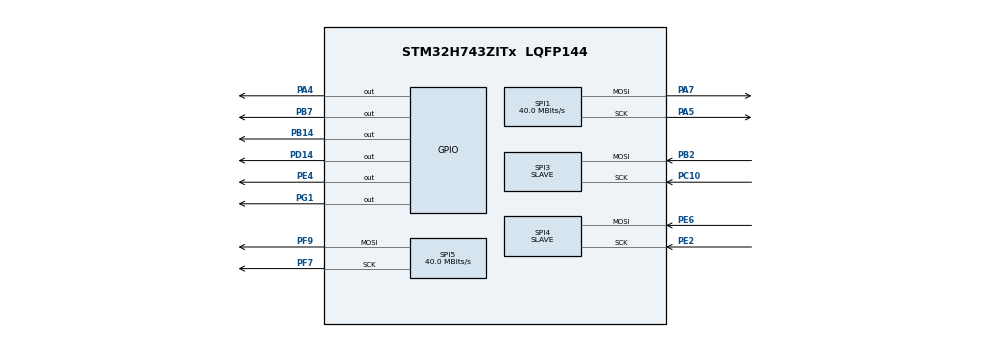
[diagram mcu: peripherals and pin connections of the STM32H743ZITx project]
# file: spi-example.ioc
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CORTEX_M7.CPU_DCache=Enabled
CORTEX_M7.CPU_ICache=Enabled
Dma.Request0=SPI3_RX
Dma.Request1=SPI1_TX
Dma.Request2=SPI5_TX
Dma.Request3=SPI4_RX
Dma.SPI1_TX.1.Direction=DMA_MEMORY_TO_PERIPH
Dma.SPI1_TX.1.EventEnable=DISABLE
Dma.SPI1_TX.1.FIFOMode=DMA_FIFOMODE_DISABLE
Dma.SPI1_TX.1.Instance=DMA1_Stream0
Dma.SPI1_TX.1.MemDataAlignment=DMA_MDATAALIGN_BYTE
Dma.SPI1_TX.1.MemInc=DMA_MINC_ENABLE
Dma.SPI1_TX.1.Mode=DMA_NORMAL
Dma.SPI1_TX.1.PeriphDataAlignment=DMA_PDATAALIGN_BYTE
Dma.SPI1_TX.1.PeriphInc=DMA_PINC_DISABLE
Dma.SPI1_TX.1.Polarity=HAL_DMAMUX_REQ_GEN_RISING
Dma.SPI1_TX.1.Priority=DMA_PRIORITY_LOW
Dma.SPI1_TX.1.RequestNumber=1
Dma.SPI1_TX.1.SignalID=NONE
Dma.SPI1_TX.1.SyncEnable=DISABLE
Dma.SPI1_TX.1.SyncPolarity=HAL_DMAMUX_SYNC_NO_EVENT
Dma.SPI1_TX.1.SyncRequestNumber=1
Dma.SPI1_TX.1.SyncSignalID=NONE
Dma.SPI3_RX.0.Direction=DMA_PERIPH_TO_MEMORY
Dma.SPI3_RX.0.EventEnable=DISABLE
Dma.SPI3_RX.0.FIFOMode=DMA_FIFOMODE_DISABLE
Dma.SPI3_RX.0.Instance=DMA1_Stream1
Dma.SPI3_RX.0.MemDataAlignment=DMA_MDATAALIGN_BYTE
Dma.SPI3_RX.0.MemInc=DMA_MINC_ENABLE
Dma.SPI3_RX.0.Mode=DMA_NORMAL
Dma.SPI3_RX.0.PeriphDataAlignment=DMA_PDATAALIGN_BYTE
Dma.SPI3_RX.0.PeriphInc=DMA_PINC_DISABLE
Dma.SPI3_RX.0.Polarity=HAL_DMAMUX_REQ_GEN_RISING
Dma.SPI3_RX.0.Priority=DMA_PRIORITY_LOW
Dma.SPI3_RX.0.RequestNumber=1
Dma.SPI3_RX.0.SignalID=NONE
Dma.SPI3_RX.0.SyncEnable=DISABLE
Dma.SPI3_RX.0.SyncPolarity=HAL_DMAMUX_SYNC_NO_EVENT
Dma.SPI3_RX.0.SyncRequestNumber=1
Dma.SPI3_RX.0.SyncSignalID=NONE
Dma.SPI4_RX.3.Direction=DMA_PERIPH_TO_MEMORY
Dma.SPI4_RX.3.EventEnable=DISABLE
Dma.SPI4_RX.3.FIFOMode=DMA_FIFOMODE_DISABLE
Dma.SPI4_RX.3.Instance=DMA2_Stream0
Dma.SPI4_RX.3.MemDataAlignment=DMA_MDATAALIGN_BYTE
Dma.SPI4_RX.3.MemInc=DMA_MINC_ENABLE
Dma.SPI4_RX.3.Mode=DMA_NORMAL
Dma.SPI4_RX.3.PeriphDataAlignment=DMA_PDATAALIGN_BYTE
Dma.SPI4_RX.3.PeriphInc=DMA_PINC_DISABLE
Dma.SPI4_RX.3.Polarity=HAL_DMAMUX_REQ_GEN_RISING
Dma.SPI4_RX.3.Priority=DMA_PRIORITY_LOW
Dma.SPI4_RX.3.RequestNumber=1
Dma.SPI4_RX.3.SignalID=NONE
Dma.SPI4_RX.3.SyncEnable=DISABLE
Dma.SPI4_RX.3.SyncPolarity=HAL_DMAMUX_SYNC_NO_EVENT
Dma.SPI4_RX.3.SyncRequestNumber=1
Dma.SPI4_RX.3.SyncSignalID=NONE
Dma.SPI5_TX.2.Direction=DMA_MEMORY_TO_PERIPH
Dma.SPI5_TX.2.EventEnable=DISABLE
Dma.SPI5_TX.2.FIFOMode=DMA_FIFOMODE_DISABLE
Dma.SPI5_TX.2.Instance=DMA2_Stream1
Dma.SPI5_TX.2.MemDataAlignment=DMA_MDATAALIGN_BYTE
Dma.SPI5_TX.2.MemInc=DMA_MINC_ENABLE
Dma.SPI5_TX.2.Mode=DMA_NORMAL
Dma.SPI5_TX.2.PeriphDataAlignment=DMA_PDATAALIGN_BYTE
Dma.SPI5_TX.2.PeriphInc=DMA_PINC_DISABLE
Dma.SPI5_TX.2.Polarity=HAL_DMAMUX_REQ_GEN_RISING
Dma.SPI5_TX.2.Priority=DMA_PRIORITY_LOW
Dma.SPI5_TX.2.RequestNumber=1
Dma.SPI5_TX.2.SignalID=NONE
Dma.SPI5_TX.2.SyncEnable=DISABLE
Dma.SPI5_TX.2.SyncPolarity=HAL_DMAMUX_SYNC_NO_EVENT
Dma.SPI5_TX.2.SyncRequestNumber=1
Dma.SPI5_TX.2.SyncSignalID=NONE
FREERTOS.Mutexes01=ch1Mutex,Dynamic,NULL;ch2Mutex,Dynamic,NULL
FREERTOS.Tasks01=ch1Task,24,1024,StartChannel1Task,Default,NULL,Dynamic,NULL,NULL;ch2Task,24,1024,StartChannel2Task,Default,NULL,Dynamic,NULL,NULL
Mcu.Family=STM32H7
Mcu.Name=STM32H743ZITx
Mcu.Package=LQFP144
NVIC.DMA1_Stream0_IRQn=true\:0\:0\:false\:false\:true\:false\:false\:true
NVIC.DMA1_Stream1_IRQn=true\:0\:0\:false\:false\:true\:false\:false\:true
NVIC.DMA2_Stream0_IRQn=true\:0\:0\:false\:false\:true\:false\:false\:true
NVIC.DMA2_Stream1_IRQn=true\:0\:0\:false\:false\:true\:false\:false\:true
NVIC.PriorityGroup=NVIC_PRIORITYGROUP_4
NVIC.SPI1_IRQn=true\:5\:0\:false\:false\:true\:true\:false\:true
NVIC.SPI3_IRQn=true\:5\:0\:false\:false\:true\:true\:false\:true
NVIC.SPI4_IRQn=true\:5\:0\:false\:false\:true\:true\:false\:true
NVIC.SPI5_IRQn=true\:5\:0\:false\:false\:true\:true\:false\:true
NVIC.TIM8_UP_TIM13_IRQn=true\:0\:0\:false\:false\:true\:false\:false\:true
NVIC.TimeBase=TIM8_UP_TIM13_IRQn
NVIC.TimeBaseIP=TIM13
PA13\ (JTMS/SWDIO).Mode=Serial_Wire
PA13\ (JTMS/SWDIO).Signal=DEBUG_JTMS-SWDIO
PA14\ (JTCK/SWCLK).Mode=Serial_Wire
PA14\ (JTCK/SWCLK).Signal=DEBUG_JTCK-SWCLK
PA4.GPIO_ModeDefaultOutputPP=GPIO_MODE_OUTPUT_OD
PA4.GPIO_PuPd=GPIO_PULLUP
PA4.Signal=GPIO_Output
PA5.GPIO_Speed=GPIO_SPEED_FREQ_MEDIUM
PA5.Mode=TX_Only_Simplex_Unidirect_Master
PA5.Signal=SPI1_SCK
PA7.GPIO_Speed=GPIO_SPEED_FREQ_MEDIUM
PA7.Mode=TX_Only_Simplex_Unidirect_Master
PA7.Signal=SPI1_MOSI
PB14.Signal=GPIO_Output
PB2.GPIO_Speed=GPIO_SPEED_FREQ_MEDIUM
PB2.Mode=RX_Only_Simplex_Unidirect_Slave
PB2.Signal=SPI3_MOSI
PB7.Signal=GPIO_Output
PC10.GPIO_Speed=GPIO_SPEED_FREQ_MEDIUM
PC10.Mode=RX_Only_Simplex_Unidirect_Slave
PC10.Signal=SPI3_SCK
PD14.GPIO_ModeDefaultOutputPP=GPIO_MODE_OUTPUT_OD
PD14.GPIO_PuPd=GPIO_PULLUP
PD14.Signal=GPIO_Output
PE2.GPIO_Speed=GPIO_SPEED_FREQ_MEDIUM
PE2.Mode=RX_Only_Simplex_Unidirect_Slave
PE2.Signal=SPI4_SCK
PE4.GPIO_ModeDefaultOutputPP=GPIO_MODE_OUTPUT_OD
PE4.GPIO_PuPd=GPIO_PULLUP
PE4.Signal=GPIO_Output
PE6.GPIO_Speed=GPIO_SPEED_FREQ_MEDIUM
PE6.Mode=RX_Only_Simplex_Unidirect_Slave
PE6.Signal=SPI4_MOSI
PF7.GPIO_PuPd=GPIO_NOPULL
PF7.GPIO_Speed=GPIO_SPEED_FREQ_MEDIUM
PF7.Mode=TX_Only_Simplex_Unidirect_Master
PF7.Signal=SPI5_SCK
PF9.GPIO_Speed=GPIO_SPEED_FREQ_MEDIUM
PF9.Mode=TX_Only_Simplex_Unidirect_Master
PF9.Signal=SPI5_MOSI
PG1.GPIO_ModeDefaultOutputPP=GPIO_MODE_OUTPUT_OD
PG1.GPIO_PuPd=GPIO_PULLUP
PG1.Signal=GPIO_Output
PH0-OSC_IN\ (PH0).Mode=HSE-External-Oscillator
PH0-OSC_IN\ (PH0).Signal=RCC_OSC_IN
PH1-OSC_OUT\ (PH1).Mode=HSE-External-Oscillator
PH1-OSC_OUT\ (PH1).Signal=RCC_OSC_OUT
ProjectManager.HeapSize=0x2000
ProjectManager.StackSize=0x4000
ProjectManager.TargetToolchain=EWARM V8.32
RCC.ADCFreq_Value=160000000
RCC.APB1Freq_Value=100000000
RCC.APB2Freq_Value=100000000
RCC.APB3Freq_Value=100000000
RCC.APB4Freq_Value=100000000
RCC.CortexFreq_Value=400000000
RCC.D1PPRE=RCC_APB3_DIV2
RCC.D2PPRE1=RCC_APB1_DIV2
RCC.D2PPRE2=RCC_APB2_DIV2
RCC.D3PPRE=RCC_APB4_DIV2
RCC.DIVM1=1
RCC.DIVM2=2
RCC.DIVM3=2
RCC.DIVN1=100
RCC.DIVN2=80
RCC.DIVN3=80
RCC.HCLKFreq_Value=200000000
RCC.HPRE=RCC_HCLK_DIV2
RCC.HSE_VALUE=8000000
RCC.PLLSourceVirtual=RCC_PLLSOURCE_HSE
RCC.PWR_Regulator_Voltage_Scale=PWR_REGULATOR_VOLTAGE_SCALE1
RCC.SPI123CLockSelection=RCC_SPI123CLKSOURCE_PLL2
RCC.SYSCLKFreq_VALUE=400000000
RCC.SYSCLKSource=RCC_SYSCLKSOURCE_PLLCLK
RCC.Spi45ClockSelection=RCC_SPI45CLKSOURCE_PLL3
RCC.USBFreq_Value=400000000
SPI1.BaudRatePrescaler=SPI_BAUDRATEPRESCALER_4
SPI1.CRCCalculation=SPI_CRCCALCULATION_DISABLE
SPI1.CalculateBaudRate=40.0 MBits/s
SPI1.DataSize=SPI_DATASIZE_8BIT
SPI1.Direction=SPI_DIRECTION_2LINES_TXONLY
SPI1.MasterInterDataIdleness=SPI_MASTER_INTERDATA_IDLENESS_00CYCLE
SPI1.MasterSSIdleness=SPI_MASTER_SS_IDLENESS_00CYCLE
SPI1.Mode=SPI_MODE_MASTER
SPI1.VirtualType=VM_MASTER
SPI3.CRCCalculation=SPI_CRCCALCULATION_DISABLE
SPI3.DataSize=SPI_DATASIZE_8BIT
SPI3.Direction=SPI_DIRECTION_2LINES_RXONLY
SPI3.MasterInterDataIdleness=SPI_MASTER_INTERDATA_IDLENESS_00CYCLE
SPI3.MasterSSIdleness=SPI_MASTER_SS_IDLENESS_00CYCLE
SPI3.Mode=SPI_MODE_SLAVE
SPI3.TIMode=SPI_TIMODE_DISABLE
SPI3.VirtualType=VM_SLAVE
SPI4.DataSize=SPI_DATASIZE_8BIT
SPI4.Direction=SPI_DIRECTION_2LINES_RXONLY
SPI4.Mode=SPI_MODE_SLAVE
SPI4.VirtualType=VM_SLAVE
SPI5.BaudRatePrescaler=SPI_BAUDRATEPRESCALER_4
SPI5.CalculateBaudRate=40.0 MBits/s
SPI5.DataSize=SPI_DATASIZE_8BIT
SPI5.Direction=SPI_DIRECTION_2LINES_TXONLY
SPI5.Mode=SPI_MODE_MASTER
SPI5.VirtualType=VM_MASTER
VP_FREERTOS_VS_CMSIS_V2.Mode=CMSIS_V2
VP_SYS_VS_tim13.Mode=TIM13
board=custom

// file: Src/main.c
/* USER CODE BEGIN Header */
/**
  ******************************************************************************
  * @file           : main.c
  * @brief          : Main program body
  ******************************************************************************
  * @attention
  *
  * <h2><center>&copy; Copyright (c) 2021 STMicroelectronics.
  * All rights reserved.</center></h2>
  *
  * This software component is licensed by ST under BSD 3-Clause license,
  * the "License"; You may not use this file except in compliance with the
  * License. You may obtain a copy of the License at:
  *                        opensource.org/licenses/BSD-3-Clause
  *
  ******************************************************************************
  */
/* USER CODE END Header */

#include "main.h"
#include "cmsis_os.h"

/* USER CODE BEGIN Includes */
#include "user_run.h"
/* USER CODE END Includes */

SPI_HandleTypeDef hspi1;
SPI_HandleTypeDef hspi3;
SPI_HandleTypeDef hspi4;
SPI_HandleTypeDef hspi5;
DMA_HandleTypeDef hdma_spi1_tx;
DMA_HandleTypeDef hdma_spi3_rx;
DMA_HandleTypeDef hdma_spi4_rx;
DMA_HandleTypeDef hdma_spi5_tx;

/* Definitions for ch1Task */
osThreadId_t ch1TaskHandle;
const osThreadAttr_t ch1Task_attributes = {
        .name = "ch1Task",
        .priority = (osPriority_t) osPriorityNormal,
        .stack_size = 1024 * 4
};
/* Definitions for ch2Task */
osThreadId_t ch2TaskHandle;
const osThreadAttr_t ch2Task_attributes = {
        .name = "ch2Task",
        .priority = (osPriority_t) osPriorityNormal,
        .stack_size = 1024 * 4
};
/* Definitions for ch1Mutex */
osMutexId_t ch1MutexHandle;
const osMutexAttr_t ch1Mutex_attributes = {
        .name = "ch1Mutex"
};
/* Definitions for ch2Mutex */
osMutexId_t ch2MutexHandle;
const osMutexAttr_t ch2Mutex_attributes = {
        .name = "ch2Mutex"
};

void SystemClock_Config(void);

static void MX_GPIO_Init(void);

static void MX_DMA_Init(void);

static void MX_SPI1_Init(void);

static void MX_SPI3_Init(void);

static void MX_SPI4_Init(void);

static void MX_SPI5_Init(void);

void StartChannel1Task(void *argument);

void StartChannel2Task(void *argument);

int main(void) {

    /* Enable I-Cache---------------------------------------------------------*/
    SCB_EnableICache();

    /* Enable D-Cache---------------------------------------------------------*/
    SCB_EnableDCache();

    /* MCU Configuration--------------------------------------------------------*/

    /* Reset of all peripherals, Initializes the Flash interface and the Systick. */
    HAL_Init();

    /* Configure the system clock */
    SystemClock_Config();

    /* Initialize all configured peripherals */
    MX_GPIO_Init();
    MX_DMA_Init();
    MX_SPI1_Init();
    MX_SPI3_Init();
    MX_SPI4_Init();
    MX_SPI5_Init();

    /* Init scheduler */
    osKernelInitialize();
    /* Create the mutex(es) */
    /* creation of ch1Mutex */
    ch1MutexHandle = osMutexNew(&ch1Mutex_attributes);

    /* creation of ch2Mutex */
    ch2MutexHandle = osMutexNew(&ch2Mutex_attributes);

    /* Create the thread(s) */
    /* creation of ch1Task */
    ch1TaskHandle = osThreadNew(StartChannel1Task, NULL, &ch1Task_attributes);

    /* creation of ch2Task */
    ch2TaskHandle = osThreadNew(StartChannel2Task, NULL, &ch2Task_attributes);

    /* Start scheduler */
    osKernelStart();

    /* We should never get here as control is now taken by the scheduler */
    /* Infinite loop */

}

void SystemClock_Config(void) {
    RCC_OscInitTypeDef RCC_OscInitStruct = {0};
    RCC_ClkInitTypeDef RCC_ClkInitStruct = {0};
    RCC_PeriphCLKInitTypeDef PeriphClkInitStruct = {0};

    /** Supply configuration update enable
    */
    HAL_PWREx_ConfigSupply(PWR_LDO_SUPPLY);
    /** Configure the main internal regulator output voltage
    */
    __HAL_PWR_VOLTAGESCALING_CONFIG(PWR_REGULATOR_VOLTAGE_SCALE1);

    while (!__HAL_PWR_GET_FLAG(PWR_FLAG_VOSRDY)) {}
    /** Macro to configure the PLL clock source
    */
    __HAL_RCC_PLL_PLLSOURCE_CONFIG(RCC_PLLSOURCE_HSE);
    /** Initializes the CPU, AHB and APB busses clocks
    */
    RCC_OscInitStruct.OscillatorType = RCC_OSCILLATORTYPE_HSE;
    RCC_OscInitStruct.HSEState = RCC_HSE_ON;
    RCC_OscInitStruct.PLL.PLLState = RCC_PLL_ON;
    RCC_OscInitStruct.PLL.PLLSource = RCC_PLLSOURCE_HSE;
    RCC_OscInitStruct.PLL.PLLM = 1;
    RCC_OscInitStruct.PLL.PLLN = 100;
    RCC_OscInitStruct.PLL.PLLP = 2;
    RCC_OscInitStruct.PLL.PLLQ = 2;
    RCC_OscInitStruct.PLL.PLLR = 2;
    RCC_OscInitStruct.PLL.PLLRGE = RCC_PLL1VCIRANGE_3;
    RCC_OscInitStruct.PLL.PLLVCOSEL = RCC_PLL1VCOWIDE;
    RCC_OscInitStruct.PLL.PLLFRACN = 0;
    if (HAL_RCC_OscConfig(&RCC_OscInitStruct) != HAL_OK) {
        Error_Handler();
    }
    /** Initializes the CPU, AHB and APB busses clocks
    */
    RCC_ClkInitStruct.ClockType = RCC_CLOCKTYPE_HCLK | RCC_CLOCKTYPE_SYSCLK
                                  | RCC_CLOCKTYPE_PCLK1 | RCC_CLOCKTYPE_PCLK2
                                  | RCC_CLOCKTYPE_D3PCLK1 | RCC_CLOCKTYPE_D1PCLK1;
    RCC_ClkInitStruct.SYSCLKSource = RCC_SYSCLKSOURCE_PLLCLK;
    RCC_ClkInitStruct.SYSCLKDivider = RCC_SYSCLK_DIV1;
    RCC_ClkInitStruct.AHBCLKDivider = RCC_HCLK_DIV2;
    RCC_ClkInitStruct.APB3CLKDivider = RCC_APB3_DIV2;
    RCC_ClkInitStruct.APB1CLKDivider = RCC_APB1_DIV2;
    RCC_ClkInitStruct.APB2CLKDivider = RCC_APB2_DIV2;
    RCC_ClkInitStruct.APB4CLKDivider = RCC_APB4_DIV2;

    if (HAL_RCC_ClockConfig(&RCC_ClkInitStruct, FLASH_LATENCY_2) != HAL_OK) {
        Error_Handler();
    }
    PeriphClkInitStruct.PeriphClockSelection = RCC_PERIPHCLK_SPI5 | RCC_PERIPHCLK_SPI4
                                               | RCC_PERIPHCLK_SPI3 | RCC_PERIPHCLK_SPI1;
    PeriphClkInitStruct.PLL2.PLL2M = 2;
    PeriphClkInitStruct.PLL2.PLL2N = 80;
    PeriphClkInitStruct.PLL2.PLL2P = 2;
    PeriphClkInitStruct.PLL2.PLL2Q = 2;
    PeriphClkInitStruct.PLL2.PLL2R = 2;
    PeriphClkInitStruct.PLL2.PLL2RGE = RCC_PLL2VCIRANGE_2;
    PeriphClkInitStruct.PLL2.PLL2VCOSEL = RCC_PLL2VCOWIDE;
    PeriphClkInitStruct.PLL2.PLL2FRACN = 0;
    PeriphClkInitStruct.PLL3.PLL3M = 2;
    PeriphClkInitStruct.PLL3.PLL3N = 80;
    PeriphClkInitStruct.PLL3.PLL3P = 2;
    PeriphClkInitStruct.PLL3.PLL3Q = 2;
    PeriphClkInitStruct.PLL3.PLL3R = 2;
    PeriphClkInitStruct.PLL3.PLL3RGE = RCC_PLL3VCIRANGE_2;
    PeriphClkInitStruct.PLL3.PLL3VCOSEL = RCC_PLL3VCOWIDE;
    PeriphClkInitStruct.PLL3.PLL3FRACN = 0;
    PeriphClkInitStruct.Spi123ClockSelection = RCC_SPI123CLKSOURCE_PLL2;
    PeriphClkInitStruct.Spi45ClockSelection = RCC_SPI45CLKSOURCE_PLL3;
    if (HAL_RCCEx_PeriphCLKConfig(&PeriphClkInitStruct) != HAL_OK) {
        Error_Handler();
    }
}

static void MX_SPI1_Init(void) {

    /* SPI1 parameter configuration*/
    hspi1.Instance = SPI1;
    hspi1.Init.Mode = SPI_MODE_MASTER;
    hspi1.Init.Direction = SPI_DIRECTION_2LINES_TXONLY;
    hspi1.Init.DataSize = SPI_DATASIZE_8BIT;
    hspi1.Init.CLKPolarity = SPI_POLARITY_LOW;
    hspi1.Init.CLKPhase = SPI_PHASE_1EDGE;
    hspi1.Init.NSS = SPI_NSS_SOFT;
    hspi1.Init.BaudRatePrescaler = SPI_BAUDRATEPRESCALER_4;
    hspi1.Init.FirstBit = SPI_FIRSTBIT_MSB;
    hspi1.Init.TIMode = SPI_TIMODE_DISABLE;
    hspi1.Init.CRCCalculation = SPI_CRCCALCULATION_DISABLE;
    hspi1.Init.CRCPolynomial = 0x0;
    hspi1.Init.NSSPMode = SPI_NSS_PULSE_ENABLE;
    hspi1.Init.NSSPolarity = SPI_NSS_POLARITY_LOW;
    hspi1.Init.FifoThreshold = SPI_FIFO_THRESHOLD_01DATA;
    hspi1.Init.TxCRCInitializationPattern = SPI_CRC_INITIALIZATION_ALL_ZERO_PATTERN;
    hspi1.Init.RxCRCInitializationPattern = SPI_CRC_INITIALIZATION_ALL_ZERO_PATTERN;
    hspi1.Init.MasterSSIdleness = SPI_MASTER_SS_IDLENESS_00CYCLE;
    hspi1.Init.MasterInterDataIdleness = SPI_MASTER_INTERDATA_IDLENESS_00CYCLE;
    hspi1.Init.MasterReceiverAutoSusp = SPI_MASTER_RX_AUTOSUSP_DISABLE;
    hspi1.Init.MasterKeepIOState = SPI_MASTER_KEEP_IO_STATE_DISABLE;
    hspi1.Init.IOSwap = SPI_IO_SWAP_DISABLE;
    if (HAL_SPI_Init(&hspi1) != HAL_OK) {
        Error_Handler();
    }

}

static void MX_SPI3_Init(void) {

    /* SPI3 parameter configuration*/
    hspi3.Instance = SPI3;
    hspi3.Init.Mode = SPI_MODE_SLAVE;
    hspi3.Init.Direction = SPI_DIRECTION_2LINES_RXONLY;
    hspi3.Init.DataSize = SPI_DATASIZE_8BIT;
    hspi3.Init.CLKPolarity = SPI_POLARITY_LOW;
    hspi3.Init.CLKPhase = SPI_PHASE_1EDGE;
    hspi3.Init.NSS = SPI_NSS_SOFT;
    hspi3.Init.FirstBit = SPI_FIRSTBIT_MSB;
    hspi3.Init.TIMode = SPI_TIMODE_DISABLE;
    hspi3.Init.CRCCalculation = SPI_CRCCALCULATION_DISABLE;
    hspi3.Init.CRCPolynomial = 0x0;
    hspi3.Init.NSSPMode = SPI_NSS_PULSE_DISABLE;
    hspi3.Init.NSSPolarity = SPI_NSS_POLARITY_LOW;
    hspi3.Init.FifoThreshold = SPI_FIFO_THRESHOLD_01DATA;
    hspi3.Init.TxCRCInitializationPattern = SPI_CRC_INITIALIZATION_ALL_ZERO_PATTERN;
    hspi3.Init.RxCRCInitializationPattern = SPI_CRC_INITIALIZATION_ALL_ZERO_PATTERN;
    hspi3.Init.MasterSSIdleness = SPI_MASTER_SS_IDLENESS_00CYCLE;
    hspi3.Init.MasterInterDataIdleness = SPI_MASTER_INTERDATA_IDLENESS_00CYCLE;
    hspi3.Init.MasterReceiverAutoSusp = SPI_MASTER_RX_AUTOSUSP_DISABLE;
    hspi3.Init.MasterKeepIOState = SPI_MASTER_KEEP_IO_STATE_DISABLE;
    hspi3.Init.IOSwap = SPI_IO_SWAP_DISABLE;
    if (HAL_SPI_Init(&hspi3) != HAL_OK) {
        Error_Handler();
    }

}

static void MX_SPI4_Init(void) {

    /* SPI4 parameter configuration*/
    hspi4.Instance = SPI4;
    hspi4.Init.Mode = SPI_MODE_SLAVE;
    hspi4.Init.Direction = SPI_DIRECTION_2LINES_RXONLY;
    hspi4.Init.DataSize = SPI_DATASIZE_8BIT;
    hspi4.Init.CLKPolarity = SPI_POLARITY_LOW;
    hspi4.Init.CLKPhase = SPI_PHASE_1EDGE;
    hspi4.Init.NSS = SPI_NSS_SOFT;
    hspi4.Init.FirstBit = SPI_FIRSTBIT_MSB;
    hspi4.Init.TIMode = SPI_TIMODE_DISABLE;
    hspi4.Init.CRCCalculation = SPI_CRCCALCULATION_DISABLE;
    hspi4.Init.CRCPolynomial = 0x0;
    hspi4.Init.NSSPMode = SPI_NSS_PULSE_DISABLE;
    hspi4.Init.NSSPolarity = SPI_NSS_POLARITY_LOW;
    hspi4.Init.FifoThreshold = SPI_FIFO_THRESHOLD_01DATA;
    hspi4.Init.TxCRCInitializationPattern = SPI_CRC_INITIALIZATION_ALL_ZERO_PATTERN;
    hspi4.Init.RxCRCInitializationPattern = SPI_CRC_INITIALIZATION_ALL_ZERO_PATTERN;
    hspi4.Init.MasterSSIdleness = SPI_MASTER_SS_IDLENESS_00CYCLE;
    hspi4.Init.MasterInterDataIdleness = SPI_MASTER_INTERDATA_IDLENESS_00CYCLE;
    hspi4.Init.MasterReceiverAutoSusp = SPI_MASTER_RX_AUTOSUSP_DISABLE;
    hspi4.Init.MasterKeepIOState = SPI_MASTER_KEEP_IO_STATE_DISABLE;
    hspi4.Init.IOSwap = SPI_IO_SWAP_DISABLE;
    if (HAL_SPI_Init(&hspi4) != HAL_OK) {
        Error_Handler();
    }

}

static void MX_SPI5_Init(void) {

    /* SPI5 parameter configuration*/
    hspi5.Instance = SPI5;
    hspi5.Init.Mode = SPI_MODE_MASTER;
    hspi5.Init.Direction = SPI_DIRECTION_2LINES_TXONLY;
    hspi5.Init.DataSize = SPI_DATASIZE_8BIT;
    hspi5.Init.CLKPolarity = SPI_POLARITY_LOW;
    hspi5.Init.CLKPhase = SPI_PHASE_1EDGE;
    hspi5.Init.NSS = SPI_NSS_SOFT;
    hspi5.Init.BaudRatePrescaler = SPI_BAUDRATEPRESCALER_4;
    hspi5.Init.FirstBit = SPI_FIRSTBIT_MSB;
    hspi5.Init.TIMode = SPI_TIMODE_DISABLE;
    hspi5.Init.CRCCalculation = SPI_CRCCALCULATION_DISABLE;
    hspi5.Init.CRCPolynomial = 0x0;
    hspi5.Init.NSSPMode = SPI_NSS_PULSE_ENABLE;
    hspi5.Init.NSSPolarity = SPI_NSS_POLARITY_LOW;
    hspi5.Init.FifoThreshold = SPI_FIFO_THRESHOLD_01DATA;
    hspi5.Init.TxCRCInitializationPattern = SPI_CRC_INITIALIZATION_ALL_ZERO_PATTERN;
    hspi5.Init.RxCRCInitializationPattern = SPI_CRC_INITIALIZATION_ALL_ZERO_PATTERN;
    hspi5.Init.MasterSSIdleness = SPI_MASTER_SS_IDLENESS_00CYCLE;
    hspi5.Init.MasterInterDataIdleness = SPI_MASTER_INTERDATA_IDLENESS_00CYCLE;
    hspi5.Init.MasterReceiverAutoSusp = SPI_MASTER_RX_AUTOSUSP_DISABLE;
    hspi5.Init.MasterKeepIOState = SPI_MASTER_KEEP_IO_STATE_DISABLE;
    hspi5.Init.IOSwap = SPI_IO_SWAP_DISABLE;
    if (HAL_SPI_Init(&hspi5) != HAL_OK) {
        Error_Handler();
    }

}

static void MX_DMA_Init(void) {

    /* DMA controller clock enable */
    __HAL_RCC_DMA1_CLK_ENABLE();
    __HAL_RCC_DMA2_CLK_ENABLE();

    /* DMA interrupt init */
    /* DMA1_Stream0_IRQn interrupt configuration */
    HAL_NVIC_SetPriority(DMA1_Stream0_IRQn, 0, 0);
    HAL_NVIC_EnableIRQ(DMA1_Stream0_IRQn);
    /* DMA1_Stream1_IRQn interrupt configuration */
    HAL_NVIC_SetPriority(DMA1_Stream1_IRQn, 0, 0);
    HAL_NVIC_EnableIRQ(DMA1_Stream1_IRQn);
    /* DMA2_Stream0_IRQn interrupt configuration */
    HAL_NVIC_SetPriority(DMA2_Stream0_IRQn, 0, 0);
    HAL_NVIC_EnableIRQ(DMA2_Stream0_IRQn);
    /* DMA2_Stream1_IRQn interrupt configuration */
    HAL_NVIC_SetPriority(DMA2_Stream1_IRQn, 0, 0);
    HAL_NVIC_EnableIRQ(DMA2_Stream1_IRQn);

}

static void MX_GPIO_Init(void) {
    GPIO_InitTypeDef GPIO_InitStruct = {0};

    /* GPIO Ports Clock Enable */
    __HAL_RCC_GPIOE_CLK_ENABLE();
    __HAL_RCC_GPIOF_CLK_ENABLE();
    __HAL_RCC_GPIOH_CLK_ENABLE();
    __HAL_RCC_GPIOA_CLK_ENABLE();
    __HAL_RCC_GPIOB_CLK_ENABLE();
    __HAL_RCC_GPIOG_CLK_ENABLE();
    __HAL_RCC_GPIOD_CLK_ENABLE();
    __HAL_RCC_GPIOC_CLK_ENABLE();

    /*Configure GPIO pin Output Level */
    HAL_GPIO_WritePin(GPIOE, GPIO_PIN_4, GPIO_PIN_RESET);

    /*Configure GPIO pin Output Level */
    HAL_GPIO_WritePin(GPIOA, GPIO_PIN_4, GPIO_PIN_RESET);

    /*Configure GPIO pin Output Level */
    HAL_GPIO_WritePin(GPIOG, GPIO_PIN_1, GPIO_PIN_RESET);

    /*Configure GPIO pin Output Level */
    HAL_GPIO_WritePin(GPIOB, GPIO_PIN_14 | GPIO_PIN_7, GPIO_PIN_RESET);

    /*Configure GPIO pin Output Level */
    HAL_GPIO_WritePin(GPIOD, GPIO_PIN_14, GPIO_PIN_RESET);

    /*Configure GPIO pin : PE4 */
    GPIO_InitStruct.Pin = GPIO_PIN_4;
    GPIO_InitStruct.Mode = GPIO_MODE_OUTPUT_OD;
    GPIO_InitStruct.Pull = GPIO_PULLUP;
    GPIO_InitStruct.Speed = GPIO_SPEED_FREQ_LOW;
    HAL_GPIO_Init(GPIOE, &GPIO_InitStruct);

    /*Configure GPIO pin : PA4 */
    GPIO_InitStruct.Pin = GPIO_PIN_4;
    GPIO_InitStruct.Mode = GPIO_MODE_OUTPUT_OD;
    GPIO_InitStruct.Pull = GPIO_PULLUP;
    GPIO_InitStruct.Speed = GPIO_SPEED_FREQ_LOW;
    HAL_GPIO_Init(GPIOA, &GPIO_InitStruct);

    /*Configure GPIO pin : PG1 */
    GPIO_InitStruct.Pin = GPIO_PIN_1;
    GPIO_InitStruct.Mode = GPIO_MODE_OUTPUT_OD;
    GPIO_InitStruct.Pull = GPIO_PULLUP;
    GPIO_InitStruct.Speed = GPIO_SPEED_FREQ_LOW;
    HAL_GPIO_Init(GPIOG, &GPIO_InitStruct);

    /*Configure GPIO pins : PB14 PB7 */
    GPIO_InitStruct.Pin = GPIO_PIN_14 | GPIO_PIN_7;
    GPIO_InitStruct.Mode = GPIO_MODE_OUTPUT_PP;
    GPIO_InitStruct.Pull = GPIO_NOPULL;
    GPIO_InitStruct.Speed = GPIO_SPEED_FREQ_LOW;
    HAL_GPIO_Init(GPIOB, &GPIO_InitStruct);

    /*Configure GPIO pin : PD14 */
    GPIO_InitStruct.Pin = GPIO_PIN_14;
    GPIO_InitStruct.Mode = GPIO_MODE_OUTPUT_OD;
    GPIO_InitStruct.Pull = GPIO_PULLUP;
    GPIO_InitStruct.Speed = GPIO_SPEED_FREQ_LOW;
    HAL_GPIO_Init(GPIOD, &GPIO_InitStruct);

}

void StartChannel1Task(void *argument) {
    /* USER CODE BEGIN 5 */
    taskChannel1();
    /* USER CODE END 5 */
}

void StartChannel2Task(void *argument) {
    /* USER CODE BEGIN StartChannel2Task */
    taskChannel2();
    /* USER CODE END StartChannel2Task */
}

void HAL_TIM_PeriodElapsedCallback(TIM_HandleTypeDef *htim) {
    if (htim->Instance == TIM13) {
        HAL_IncTick();
    }
}

void Error_Handler(void) {
}

/************************ (C) COPYRIGHT STMicroelectronics *****END OF FILE****/
